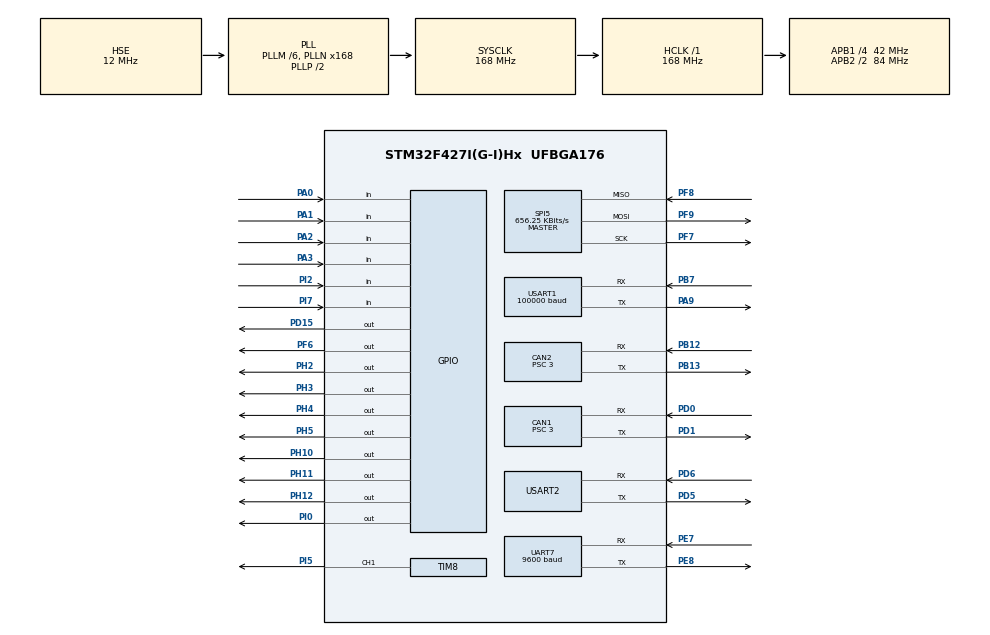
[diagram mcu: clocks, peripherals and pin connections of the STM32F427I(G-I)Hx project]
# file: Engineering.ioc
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CAN1.AWUM=ENABLE
CAN1.BS1=CAN_BS1_9TQ
CAN1.BS2=CAN_BS2_4TQ
CAN1.CalculateTimeQuantum=71.42857142857143
CAN1.Prescaler=3
CAN2.BS1=CAN_BS1_9TQ
CAN2.BS2=CAN_BS2_4TQ
CAN2.CalculateTimeQuantum=71.42857142857143
CAN2.NART=ENABLE
CAN2.Prescaler=3
Dma.Request0=USART1_RX
Dma.USART1_RX.0.Direction=DMA_PERIPH_TO_MEMORY
Dma.USART1_RX.0.FIFOMode=DMA_FIFOMODE_DISABLE
Dma.USART1_RX.0.Instance=DMA2_Stream2
Dma.USART1_RX.0.MemDataAlignment=DMA_MDATAALIGN_BYTE
Dma.USART1_RX.0.MemInc=DMA_MINC_ENABLE
Dma.USART1_RX.0.Mode=DMA_NORMAL
Dma.USART1_RX.0.PeriphDataAlignment=DMA_PDATAALIGN_BYTE
Dma.USART1_RX.0.PeriphInc=DMA_PINC_DISABLE
Dma.USART1_RX.0.Priority=DMA_PRIORITY_LOW
FREERTOS.Tasks01=defaultTask,0,128,StartDefaultTask,As weak,NULL,Dynamic,NULL,NULL
FREERTOS.configTOTAL_HEAP_SIZE=30000
Mcu.Family=STM32F4
Mcu.Name=STM32F427I(G-I)Hx
Mcu.Package=UFBGA176
NVIC.DMA2_Stream2_IRQn=true\:5\:0\:false\:false\:true\:true\:false\:true
NVIC.PriorityGroup=NVIC_PRIORITYGROUP_4
NVIC.TIM1_UP_TIM10_IRQn=true\:0\:0\:false\:false\:true\:false\:false\:true
NVIC.TimeBase=TIM1_UP_TIM10_IRQn
NVIC.TimeBaseIP=TIM10
NVIC.UART7_IRQn=true\:5\:0\:false\:false\:true\:true\:true\:true
PA0/WKUP.Signal=GPIO_Input
PA1.Signal=GPIO_Input
PA13.Mode=Trace_Asynchronous_SW
PA13.Signal=SYS_JTMS-SWDIO
PA14.Mode=Trace_Asynchronous_SW
PA14.Signal=SYS_JTCK-SWCLK
PA2.Signal=GPIO_Input
PA3.Signal=GPIO_Input
PA9.Mode=Asynchronous
PA9.Signal=USART1_TX
PB12.Mode=Slave
PB12.Signal=CAN2_RX
PB13.Mode=Slave
PB13.Signal=CAN2_TX
PB3.Mode=Trace_Asynchronous_SW
PB3.Signal=SYS_JTDO-SWO
PB7.Mode=Asynchronous
PB7.Signal=USART1_RX
PD0.Mode=Master
PD0.Signal=CAN1_RX
PD1.Mode=Master
PD1.Signal=CAN1_TX
PD15.Signal=GPIO_Output
PD5.Mode=Asynchronous
PD5.Signal=USART2_TX
PD6.Mode=Asynchronous
PD6.Signal=USART2_RX
PE7.Mode=Asynchronous
PE7.Signal=UART7_RX
PE8.Mode=Asynchronous
PE8.Signal=UART7_TX
PF6.Signal=GPIO_Output
PF7.Mode=Full_Duplex_Master
PF7.Signal=SPI5_SCK
PF8.Mode=Full_Duplex_Master
PF8.Signal=SPI5_MISO
PF9.Mode=Full_Duplex_Master
PF9.Signal=SPI5_MOSI
PH0/OSC_IN.Mode=HSE-External-Oscillator
PH0/OSC_IN.Signal=RCC_OSC_IN
PH1/OSC_OUT.Mode=HSE-External-Oscillator
PH1/OSC_OUT.Signal=RCC_OSC_OUT
PH10.Signal=GPIO_Output
PH11.Signal=GPIO_Output
PH12.Signal=GPIO_Output
PH2.Signal=GPIO_Output
PH3.Signal=GPIO_Output
PH4.Signal=GPIO_Output
PH5.Signal=GPIO_Output
PI0.Signal=GPIO_Output
PI2.Signal=GPIO_Input
PI5.Signal=S_TIM8_CH1
PI7.Signal=GPIO_Input
ProjectManager.HeapSize=0x200
ProjectManager.StackSize=0x400
ProjectManager.TargetToolchain=SW4STM32
RCC.48MHZClocksFreq_Value=84000000
RCC.AHBFreq_Value=168000000
RCC.APB1CLKDivider=RCC_HCLK_DIV4
RCC.APB1Freq_Value=42000000
RCC.APB1TimFreq_Value=84000000
RCC.APB2CLKDivider=RCC_HCLK_DIV2
RCC.APB2Freq_Value=84000000
RCC.APB2TimFreq_Value=168000000
RCC.CortexFreq_Value=168000000
RCC.HCLKFreq_Value=168000000
RCC.HSE_VALUE=12000000
RCC.HSI_VALUE=16000000
RCC.LSE_VALUE=32768
RCC.PLLM=6
RCC.PLLN=168
RCC.PLLSourceVirtual=RCC_PLLSOURCE_HSE
RCC.SYSCLKFreq_VALUE=168000000
RCC.SYSCLKSource=RCC_SYSCLKSOURCE_PLLCLK
RCC.VCOOutputFreq_Value=336000000
SH.S_TIM8_CH1.0=TIM8_CH1,PWM Generation1 CH1
SPI5.BaudRatePrescaler=SPI_BAUDRATEPRESCALER_128
SPI5.CalculateBaudRate=656.25 KBits/s
SPI5.Direction=SPI_DIRECTION_2LINES
SPI5.Mode=SPI_MODE_MASTER
SPI5.VirtualType=VM_MASTER
TIM8.Channel-PWM\ Generation1\ CH1=TIM_CHANNEL_1
TIM8.Period=19999
TIM8.Prescaler=167
TIM8.Pulse-PWM\ Generation1\ CH1=500
UART7.BaudRate=9600
UART7.VirtualMode=Asynchronous
USART1.BaudRate=100000
USART1.Mode=MODE_RX
USART1.VirtualMode=VM_ASYNC
USART2.VirtualMode=VM_ASYNC
VP_FREERTOS_VS_CMSIS_V1.Mode=CMSIS_V1
VP_SYS_VS_tim10.Mode=TIM10
board=custom

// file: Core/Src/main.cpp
/* USER CODE BEGIN Header */
/**
 ******************************************************************************
 * @file           : main.c
 * @brief          : Main program body
 ******************************************************************************
 * @attention
 *
 * <h2><center>&copy; Copyright (c) 2019 STMicroelectronics.
 * All rights reserved.</center></h2>
 *
 * This software component is licensed by ST under Ultimate Liberty license
 * SLA0044, the "License"; You may not use this file except in compliance with
 * the License. You may obtain a copy of the License at:
 *                             www.st.com/SLA0044
 *
 ******************************************************************************
 */
/* USER CODE END Header */

#include "main.h"
#include "can.h"
#include "cmsis_os.h"
#include "dma.h"
#include "gpio.h"
#include "spi.h"
#include "tim.h"
#include "usart.h"
#include <Inc/user.h>

void SystemClock_Config(void);
void MX_FREERTOS_Init(void);

int main(void)
{

  /* MCU Configuration--------------------------------------------------------*/

  /* Reset of all peripherals, Initializes the Flash interface and the Systick. */
  HAL_Init();

  /* Configure the system clock */
  SystemClock_Config();

  /* Initialize all configured peripherals */
  MX_GPIO_Init();
  MX_DMA_Init();
  MX_CAN1_Init();
  MX_CAN2_Init();
  MX_SPI5_Init();
  MX_TIM8_Init();
  MX_UART7_Init();
  MX_USART1_UART_Init();
  MX_USART2_UART_Init();
  /* USER CODE BEGIN 2 */
  user_main();
  /* USER CODE END 2 */

  /* Call init function for freertos objects (in freertos.c) */
  MX_FREERTOS_Init();

  /* Start scheduler */
  osKernelStart();

  /* We should never get here as control is now taken by the scheduler */

  /* Infinite loop */
  while (1) {

  }
}

void SystemClock_Config(void)
{
  RCC_OscInitTypeDef RCC_OscInitStruct = {0};
  RCC_ClkInitTypeDef RCC_ClkInitStruct = {0};

  /** Configure the main internal regulator output voltage
  */
  __HAL_RCC_PWR_CLK_ENABLE();
  __HAL_PWR_VOLTAGESCALING_CONFIG(PWR_REGULATOR_VOLTAGE_SCALE1);
  /** Initializes the CPU, AHB and APB busses clocks
  */
  RCC_OscInitStruct.OscillatorType = RCC_OSCILLATORTYPE_HSE;
  RCC_OscInitStruct.HSEState = RCC_HSE_ON;
  RCC_OscInitStruct.PLL.PLLState = RCC_PLL_ON;
  RCC_OscInitStruct.PLL.PLLSource = RCC_PLLSOURCE_HSE;
  RCC_OscInitStruct.PLL.PLLM = 6;
  RCC_OscInitStruct.PLL.PLLN = 168;
  RCC_OscInitStruct.PLL.PLLP = RCC_PLLP_DIV2;
  RCC_OscInitStruct.PLL.PLLQ = 4;
  if (HAL_RCC_OscConfig(&RCC_OscInitStruct) != HAL_OK)
  {
    Error_Handler();
  }
  /** Initializes the CPU, AHB and APB busses clocks
  */
  RCC_ClkInitStruct.ClockType = RCC_CLOCKTYPE_HCLK|RCC_CLOCKTYPE_SYSCLK
                              |RCC_CLOCKTYPE_PCLK1|RCC_CLOCKTYPE_PCLK2;
  RCC_ClkInitStruct.SYSCLKSource = RCC_SYSCLKSOURCE_PLLCLK;
  RCC_ClkInitStruct.AHBCLKDivider = RCC_SYSCLK_DIV1;
  RCC_ClkInitStruct.APB1CLKDivider = RCC_HCLK_DIV4;
  RCC_ClkInitStruct.APB2CLKDivider = RCC_HCLK_DIV2;

  if (HAL_RCC_ClockConfig(&RCC_ClkInitStruct, FLASH_LATENCY_5) != HAL_OK)
  {
    Error_Handler();
  }
}

void HAL_TIM_PeriodElapsedCallback(TIM_HandleTypeDef *htim)
{
  if (htim->Instance == TIM10) {
    HAL_IncTick();
  }
}

void Error_Handler(void)
{
}

#ifdef  USE_FULL_ASSERT
/**
  * @brief  Reports the name of the source file and the source line number
  *         where the assert_param error has occurred.
  * @param  file: pointer to the source file name
  * @param  line: assert_param error line source number
  * @retval None
  */
void assert_failed(uint8_t *file, uint32_t line)
{
  /* USER CODE BEGIN 6 */
  /* User can add his own implementation to report the file name and line
     number,
     tex: printf("Wrong parameters value: file %s on line %d\r\n", file, line)
   */
  /* USER CODE END 6 */
}
#endif /* USE_FULL_ASSERT */

/************************ (C) COPYRIGHT STMicroelectronics *****END OF FILE****/
